# MSP430FR4133 register map
Registers are 16-bit, read-write, reset 0x0 unless marked. A register's access mark holds for its fields unless they carry their own. Offsets are from the block's base; lines under a group give offsets from that group; [hi:lo] are bit positions; {n}, {i} and the like mark numbered series; 'fields as' and 'values as' point back to an identical list; <NAME> marks a mode.

## Memory map
0x00000100 SFR — SFR Special Function Registers
0x00000120 PMM — PMM Power Management System
0x00000140 SYS — SYS System Module
0x00000180 CS — CS Clock System
0x000001A0 FRAM
0x000001C0 CRC16
0x000001CC WATCHDOG_TIMER
0x00000200 PORT_1_2
0x00000220 PORT_3_4
0x00000240 PORT_5_6
0x00000260 PORT_7_8
0x000002EE CAPACITIVE_TOUCH_IO_0
0x00000300 TIMER_0_A3
0x00000340 TIMER_1_A3
0x000003C0 REAL_TIME_CLOCK
0x00000500 USCI_A0_UART_MODE
0x00000500 USCI_A0_SPI_MODE
0x00000540 USCI_B0_I2C_MODE
0x00000540 USCI_B0_SPI_MODE
0x00000600 LCD_E
0x00000660 BACKUP_MEMORY
0x00000700 ADC
0x0000FF80 _INTERRUPTS

## Interrupts
45 LCD_E (_INTERRUPTS) — 0xFFE2 LCD E
46 PORT2 (_INTERRUPTS) — 0xFFE4 Port 2
47 PORT1 (_INTERRUPTS) — 0xFFE6 Port 1
48 ADC (_INTERRUPTS) — 0xFFE8 ADC
49 USCI_B0 (_INTERRUPTS) — 0xFFEA USCI B0 Receive/Transmit
50 USCI_A0 (_INTERRUPTS) — 0xFFEC USCI A0 Receive/Transmit
51 WDT (_INTERRUPTS) — 0xFFEE Watchdog Timer
52 RTC (_INTERRUPTS) — 0xFFF0 RTC
53 TIMER1_A1 (_INTERRUPTS) — 0xFFF2 Timer1_A3 CC1-2, TA
54 TIMER1_A0 (_INTERRUPTS) — 0xFFF4 Timer1_A3 CC0
55 TIMER0_A1 (_INTERRUPTS) — 0xFFF6 Timer0_A3 CC1-2, TA
56 TIMER0_A0 (_INTERRUPTS) — 0xFFE8 Timer0_A3 CC0
57 UNMI (_INTERRUPTS) — 0xFFFA User Non-maskable
58 SYSNMI (_INTERRUPTS) — 0xFFFC System Non-maskable

## Further device data
msp430_svd: version=0.2.0 commit_hash=2dc0c1f

## PORT_1_2
Base 0x00000200
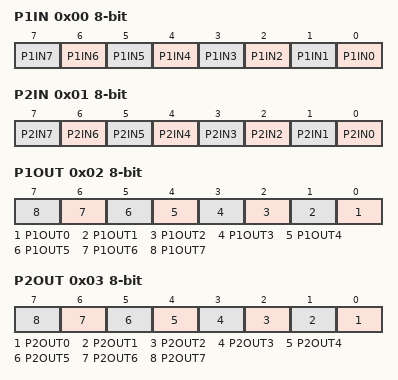
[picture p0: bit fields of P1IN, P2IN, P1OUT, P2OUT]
0x00 P1IN 8-bit — Port 1 Input
  [n] P1IN{n} (n=0..7)
0x01 P2IN 8-bit — Port 2 Input
  [n] P2IN{n} (n=0..7)
0x02 P1OUT 8-bit — Port 1 Output
  [n] P1OUT{n} (n=0..7)
0x03 P2OUT 8-bit — Port 2 Output
  [n] P2OUT{n} (n=0..7)
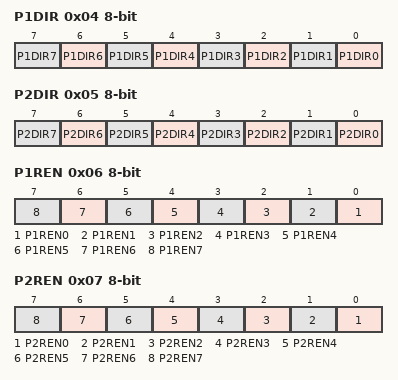
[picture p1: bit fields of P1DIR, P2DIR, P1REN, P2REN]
0x04 P1DIR 8-bit — Port 1 Direction
  [n] P1DIR{n} (n=0..7)
0x05 P2DIR 8-bit — Port 2 Direction
  [n] P2DIR{n} (n=0..7)
0x06 P1REN 8-bit — Port 1 Resistor Enable
  [n] P1REN{n} (n=0..7)
0x07 P2REN 8-bit — Port 2 Resistor Enable
  [n] P2REN{n} (n=0..7)
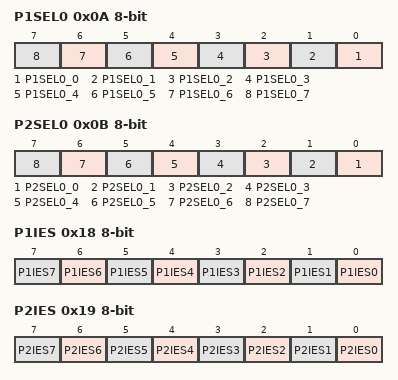
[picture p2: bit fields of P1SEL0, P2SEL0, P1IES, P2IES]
0x0A P1SEL0 8-bit — Port 1 Selection 0
  [n] P1SEL0_{n} (n=0..7)
0x0B P2SEL0 8-bit — Port 2 Selection 0
  [n] P2SEL0_{n} (n=0..7)
0x0E P1IV — Port 1 Interrupt Vector Word
0x18 P1IES 8-bit — Port 1 Interrupt Edge Select
  [n] P1IES{n} (n=0..7)
0x19 P2IES 8-bit — Port 2 Interrupt Edge Select
  [n] P2IES{n} (n=0..7)
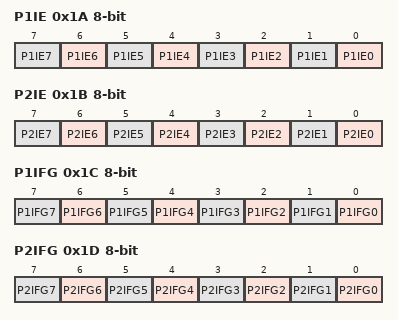
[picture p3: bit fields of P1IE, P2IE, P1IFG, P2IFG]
0x1A P1IE 8-bit — Port 1 Interrupt Enable
  [n] P1IE{n} (n=0..7)
0x1B P2IE 8-bit — Port 2 Interrupt Enable
  [n] P2IE{n} (n=0..7)
0x1C P1IFG 8-bit — Port 1 Interrupt Flag
  [n] P1IFG{n} (n=0..7)
0x1D P2IFG 8-bit — Port 2 Interrupt Flag
  [n] P2IFG{n} (n=0..7)
0x1E P2IV — Port 2 Interrupt Vector Word

## PORT_3_4
Base 0x00000220
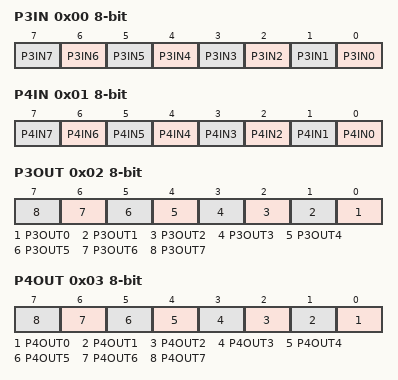
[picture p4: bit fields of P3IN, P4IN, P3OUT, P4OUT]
0x00 P3IN 8-bit — Port 3 Input
  [n] P3IN{n} (n=0..7)
0x01 P4IN 8-bit — Port 4 Input
  [n] P4IN{n} (n=0..7)
0x02 P3OUT 8-bit — Port 3 Output
  [n] P3OUT{n} (n=0..7)
0x03 P4OUT 8-bit — Port 4 Output
  [n] P4OUT{n} (n=0..7)
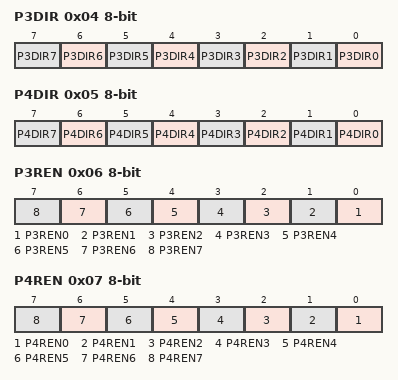
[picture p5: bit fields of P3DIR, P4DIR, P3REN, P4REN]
0x04 P3DIR 8-bit — Port 3 Direction
  [n] P3DIR{n} (n=0..7)
0x05 P4DIR 8-bit — Port 4 Direction
  [n] P4DIR{n} (n=0..7)
0x06 P3REN 8-bit — Port 3 Resistor Enable
  [n] P3REN{n} (n=0..7)
0x07 P4REN 8-bit — Port 4 Resistor Enable
  [n] P4REN{n} (n=0..7)
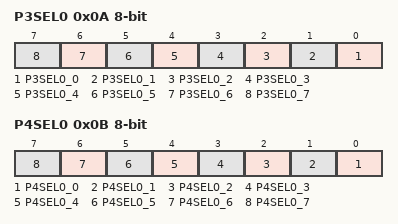
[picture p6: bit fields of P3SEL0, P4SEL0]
0x0A P3SEL0 8-bit — Port 3 Selection 0
  [n] P3SEL0_{n} (n=0..7)
0x0B P4SEL0 8-bit — Port 4 Selection 0
  [n] P4SEL0_{n} (n=0..7)

## PORT_5_6
Base 0x00000240
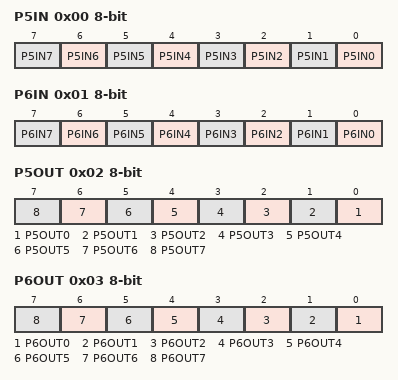
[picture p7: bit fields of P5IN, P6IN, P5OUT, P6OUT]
0x00 P5IN 8-bit — Port 5 Input
  [n] P5IN{n} (n=0..7)
0x01 P6IN 8-bit — Port 6 Input
  [n] P6IN{n} (n=0..7)
0x02 P5OUT 8-bit — Port 5 Output
  [n] P5OUT{n} (n=0..7)
0x03 P6OUT 8-bit — Port 6 Output
  [n] P6OUT{n} (n=0..7)
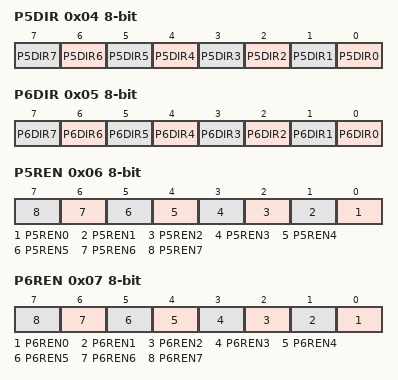
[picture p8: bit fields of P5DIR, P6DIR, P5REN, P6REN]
0x04 P5DIR 8-bit — Port 5 Direction
  [n] P5DIR{n} (n=0..7)
0x05 P6DIR 8-bit — Port 6 Direction
  [n] P6DIR{n} (n=0..7)
0x06 P5REN 8-bit — Port 5 Resistor Enable
  [n] P5REN{n} (n=0..7)
0x07 P6REN 8-bit — Port 6 Resistor Enable
  [n] P6REN{n} (n=0..7)
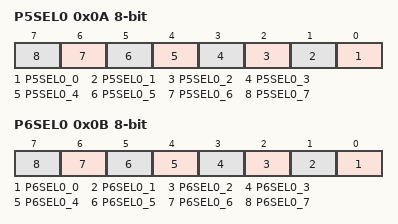
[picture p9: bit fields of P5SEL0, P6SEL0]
0x0A P5SEL0 8-bit — Port 5 Selection 0
  [n] P5SEL0_{n} (n=0..7)
0x0B P6SEL0 8-bit — Port 6 Selection 0
  [n] P6SEL0_{n} (n=0..7)
